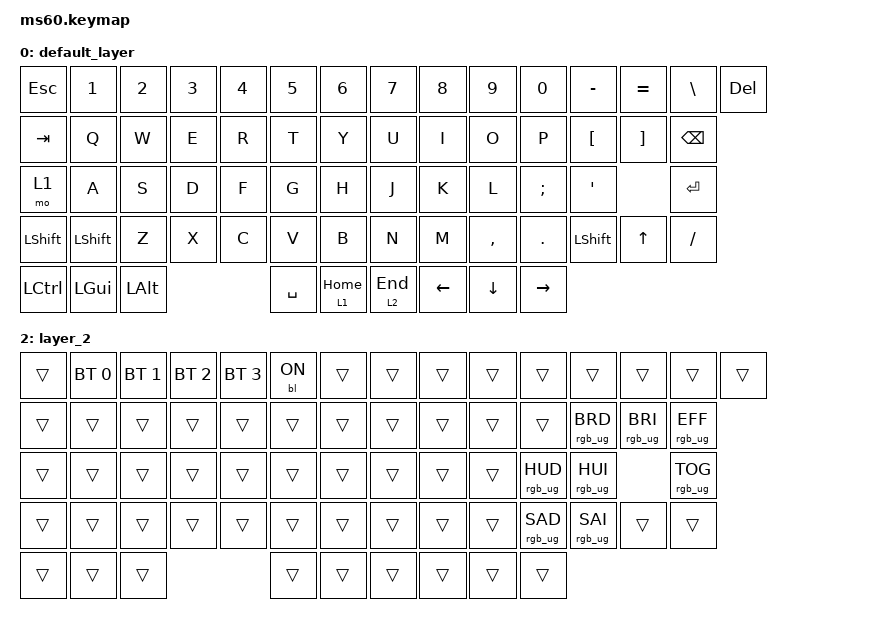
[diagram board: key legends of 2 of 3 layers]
#include <behaviors.dtsi>
#include <dt-bindings/zmk/backlight.h>
#include <dt-bindings/zmk/bt.h>
#include <dt-bindings/zmk/keys.h>
#include <dt-bindings/zmk/rgb.h>

#define BT0 BT_SEL 0
#define BT1 BT_SEL 1
#define BT2 BT_SEL 2

&mt {
    flavor = "balanced";
    quick-tap-ms = <200>;
};

&lt {
    flavor = "balanced";
    quick-tap-ms = <200>;
};

/ {
    combos {
        compatible = "zmk,combos";

        booloader {
            bindings = <&bootloader>;
            key-positions = <14 0>;
        };

        resetbleprofile {
            bindings = <&bt BT_CLR>;
            key-positions = <15 28>;
        };

        clearall {
            bindings = <&bt BT_CLR_ALL>;
            key-positions = <29 41>;
        };

        print {
            bindings = <&kp PRINTSCREEN>;
            key-positions = <13 14>;
        };

        F11111 {
            bindings = <&kp F1>;
            key-positions = <0 1>;
        };
    };

    keymap {
        compatible = "zmk,keymap";

        default_layer {
            // -------------------------------------------------------------------------------------------
            // | ESC |  1  |  2  |  3  |  4  |  5  |  6  |  7  |  8  |  9  |  0  |  -  |  =  | BKSP |BKSP|
            // | TAB  |  Q  |  W  |  E  |  R  |  T  |  Y  |  U  |  I  |  O  |  P  |  [  |  ]  |   "|"    |
            // | CAPS  |  A  |  S  |  D  |  F  |  G  |  H  |  J  |  K  |  L  |  ;  |  '  |     ENTER     |
            // |  SHIFT  |  Z  |  X  |  C  |  V  |  B  |  N  |  M  |  ,  |  .  |   SHFT   |  UP  |   /   |
            // |  CTL  |  WIN  |  ALT  |           SPACE             | FN(1) | WIN | LEFT | DOWN | RIGHT |
            // -------------------------------------------------------------------------------------------

            bindings = <
&kp ESCAPE  &kp N1     &kp N2    &kp N3  &kp N4  &kp N5     &kp N6      &kp N7     &kp N8          &kp N9          &kp N0     &kp MINUS       &kp EQUAL     &kp BACKSLASH  &kp DEL
&kp TAB     &kp Q      &kp W     &kp E   &kp R   &kp T      &kp Y       &kp U      &kp I           &kp O           &kp P      &kp LBKT        &kp RBKT      &kp BACKSPACE
&mo 1       &kp A      &kp S     &kp D   &kp F   &kp G      &kp H       &kp J      &kp K           &kp L           &kp SEMI   &kp SQT                       &kp RET
&kp LSHFT   &kp LSHFT  &kp Z     &kp X   &kp C   &kp V      &kp B       &kp N      &kp M           &kp COMMA       &kp DOT    &kp LEFT_SHIFT  &kp UP_ARROW  &kp SLASH
&kp LCTRL   &kp LGUI   &kp LALT                  &kp SPACE  &lt 1 HOME  &lt 2 END  &kp LEFT_ARROW  &kp DOWN_ARROW  &kp RIGHT
            >;
        };

        rgb_layer {
            // ------------------------------------------------------------------------------------------------
            // | BT CLR | F1  | F2  | F3  | F4  | F5  | F6  | F7  | F8  | F9  | F10 | F11 | F12 | BOOT | BOOT |
            // |  BT 1   | TOG  |  UP |   | HUEUP | SATUP | BRIUP | SPDUP |   |     |   |    |    |  RGB_efect|
            // |   BT 2   | LT |  DN  | RT | HUEDN | SATDN | BRIDN | SPDDN |   |     |   |     |  EFFECT FORW |
            // |    BT 3     |     |      |      |     |     |     |     |     |     |     |                  |
            // |   BT 4  |      |      |             TOG RGB                | PRT SCR |    |    |     |  DEL  |
            // ------------------------------------------------------------------------------------------------

            bindings = <
&kp GRAVE  &kp F1    &kp F2    &kp F3     &kp F4  &kp F5  &kp F6  &kp F7  &kp F8  &kp F9  &kp F10  &kp F11  &kp F12  &trans  &trans
&trans     &trans    &kp UP    &trans     &trans  &trans  &trans  &trans  &trans  &trans  &trans   &trans   &trans   &trans
&trans     &kp LEFT  &kp DOWN  &kp RIGHT  &trans  &trans  &trans  &trans  &trans  &trans  &trans   &trans            &trans
&trans     &trans    &trans    &trans     &trans  &trans  &trans  &trans  &trans  &trans  &trans   &trans   &trans   &trans
&trans     &trans    &trans                       &trans  &trans  &trans  &trans
            >;
        };

        layer_2 {
            bindings = <
&trans  &bt BT_SEL 0  &bt BT_SEL 1  &bt BT_SEL 2  &bt BT_SEL 3  &bl BL_ON  &trans  &trans  &trans  &trans  &trans           &trans           &trans           &trans           &trans
&trans  &trans        &trans        &trans        &trans        &trans     &trans  &trans  &trans  &trans  &trans           &rgb_ug RGB_BRD  &rgb_ug RGB_BRI  &rgb_ug RGB_EFF
&trans  &trans        &trans        &trans        &trans        &trans     &trans  &trans  &trans  &trans  &rgb_ug RGB_HUD  &rgb_ug RGB_HUI                   &rgb_ug RGB_TOG
&trans  &trans        &trans        &trans        &trans        &trans     &trans  &trans  &trans  &trans  &rgb_ug RGB_SAD  &rgb_ug RGB_SAI  &trans           &trans
&trans  &trans        &trans                                    &trans     &trans  &trans  &trans  &trans  &trans
            >;
        };
    };
};
